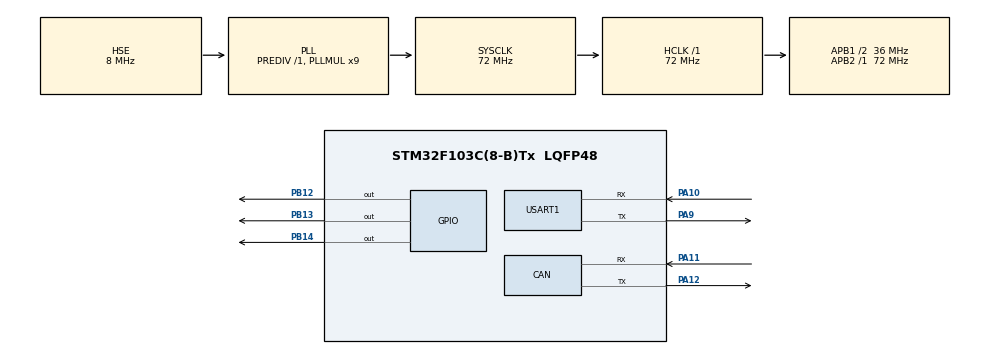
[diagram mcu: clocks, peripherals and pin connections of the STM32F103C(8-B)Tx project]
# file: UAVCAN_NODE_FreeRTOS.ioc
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CAN.CalculateTimeBit=1333
CAN.CalculateTimeQuantum=444.44444444444446
FREERTOS.Tasks01=Task01,0,128,StartTask01,Default,NULL,Dynamic,NULL,NULL;Task02,0,128,StartTask02,Default,NULL,Dynamic,NULL,NULL
Mcu.Family=STM32F1
Mcu.Name=STM32F103C(8-B)Tx
Mcu.Package=LQFP48
NVIC.PriorityGroup=NVIC_PRIORITYGROUP_4
NVIC.TIM4_IRQn=true\:0\:0\:false\:false\:true\:false\:false
NVIC.TimeBase=TIM4_IRQn
NVIC.TimeBaseIP=TIM4
NVIC.USART1_IRQn=true\:5\:0\:false\:false\:true\:true\:true
PA10.Mode=Asynchronous
PA10.Signal=USART1_RX
PA11.Mode=Master
PA11.Signal=CAN_RX
PA12.Mode=Master
PA12.Signal=CAN_TX
PA13.Mode=Trace_Asynchronous_SW
PA13.Signal=SYS_JTMS-SWDIO
PA14.Mode=Trace_Asynchronous_SW
PA14.Signal=SYS_JTCK-SWCLK
PA9.Mode=Asynchronous
PA9.Signal=USART1_TX
PB12.PinState=GPIO_PIN_SET
PB12.Signal=GPIO_Output
PB13.PinState=GPIO_PIN_SET
PB13.Signal=GPIO_Output
PB14.PinState=GPIO_PIN_SET
PB14.Signal=GPIO_Output
PB3.Mode=Trace_Asynchronous_SW
PB3.Signal=SYS_JTDO-TRACESWO
PD0-OSC_IN.Mode=HSE-External-Oscillator
PD0-OSC_IN.Signal=RCC_OSC_IN
PD1-OSC_OUT.Mode=HSE-External-Oscillator
PD1-OSC_OUT.Signal=RCC_OSC_OUT
ProjectManager.HeapSize=0x200
ProjectManager.StackSize=0x400
ProjectManager.TargetToolchain=Makefile
RCC.AHBFreq_Value=72000000
RCC.APB1CLKDivider=RCC_HCLK_DIV2
RCC.APB1Freq_Value=36000000
RCC.APB1TimFreq_Value=72000000
RCC.APB2Freq_Value=72000000
RCC.APB2TimFreq_Value=72000000
RCC.HCLKFreq_Value=72000000
RCC.PLLMUL=RCC_PLL_MUL9
RCC.PLLSourceVirtual=RCC_PLLSOURCE_HSE
RCC.SYSCLKFreq_VALUE=72000000
RCC.SYSCLKSource=RCC_SYSCLKSOURCE_PLLCLK
RCC.USBFreq_Value=72000000
USART1.VirtualMode=VM_ASYNC
VP_FREERTOS_VS_ENABLE.Mode=Enabled
VP_SYS_VS_tim4.Mode=TIM4
board=custom

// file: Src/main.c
/**
  ******************************************************************************
  * @file           : main.c
  * @brief          : Main program body
  ******************************************************************************
  * This notice applies to any and all portions of this file
  * that are not between comment pairs USER CODE BEGIN and
  * USER CODE END. Other portions of this file, whether
  * inserted by the user or by software development tools
  * are owned by their respective copyright owners.
  *
  * Copyright (c) 2018 STMicroelectronics International N.V.
  * All rights reserved.
  *
  * Redistribution and use in source and binary forms, with or without
  * modification, are permitted, provided that the following conditions are met:
  *
  * 1. Redistribution of source code must retain the above copyright notice,
  *    this list of conditions and the following disclaimer.
  * 2. Redistributions in binary form must reproduce the above copyright notice,
  *    this list of conditions and the following disclaimer in the documentation
  *    and/or other materials provided with the distribution.
  * 3. Neither the name of STMicroelectronics nor the names of other
  *    contributors to this software may be used to endorse or promote products
  *    derived from this software without specific written permission.
  * 4. This software, including modifications and/or derivative works of this
  *    software, must execute solely and exclusively on microcontroller or
  *    microprocessor devices manufactured by or for STMicroelectronics.
  * 5. Redistribution and use of this software other than as permitted under
  *    this license is void and will automatically terminate your rights under
  *    this license.
  *
  * THIS SOFTWARE IS PROVIDED BY STMICROELECTRONICS AND CONTRIBUTORS "AS IS"
  * AND ANY EXPRESS, IMPLIED OR STATUTORY WARRANTIES, INCLUDING, BUT NOT
  * LIMITED TO, THE IMPLIED WARRANTIES OF MERCHANTABILITY, FITNESS FOR A
  * PARTICULAR PURPOSE AND NON-INFRINGEMENT OF THIRD PARTY INTELLECTUAL PROPERTY
  * RIGHTS ARE DISCLAIMED TO THE FULLEST EXTENT PERMITTED BY LAW. IN NO EVENT
  * SHALL STMICROELECTRONICS OR CONTRIBUTORS BE LIABLE FOR ANY DIRECT, INDIRECT,
  * INCIDENTAL, SPECIAL, EXEMPLARY, OR CONSEQUENTIAL DAMAGES (INCLUDING, BUT NOT
  * LIMITED TO, PROCUREMENT OF SUBSTITUTE GOODS OR SERVICES; LOSS OF USE, DATA,
  * OR PROFITS; OR BUSINESS INTERRUPTION) HOWEVER CAUSED AND ON ANY THEORY OF
  * LIABILITY, WHETHER IN CONTRACT, STRICT LIABILITY, OR TORT (INCLUDING
  * NEGLIGENCE OR OTHERWISE) ARISING IN ANY WAY OUT OF THE USE OF THIS SOFTWARE,
  * EVEN IF ADVISED OF THE POSSIBILITY OF SUCH DAMAGE.
  *
  ******************************************************************************
  */
#include "main.h"
#include "stm32f1xx_hal.h"
#include "cmsis_os.h"
#include "can.h"
#include "usart.h"
#include "gpio.h"
#include "uavcan.h"

/* USER CODE BEGIN PV */
/* Private variables ---------------------------------------------------------*/

/* USER CODE END PV */

void SystemClock_Config(void);
void MX_FREERTOS_Init(void);

/* USER CODE BEGIN PFP */
/* Private function prototypes -----------------------------------------------*/

/* USER CODE END PFP */

int main(void)
{

  /* MCU Configuration----------------------------------------------------------*/

  /* Reset of all peripherals, Initializes the Flash interface and the Systick. */
  HAL_Init();

  /* Configure the system clock */
  SystemClock_Config();

  /* Initialize all configured peripherals */
  MX_GPIO_Init();
  MX_USART1_UART_Init();
  MX_CAN_Init();
  /* USER CODE BEGIN 2 */
  uavcanInit();
  /* USER CODE END 2 */

  /* Call init function for freertos objects (in freertos.c) */
  MX_FREERTOS_Init();

  /* Start scheduler */
  osKernelStart();

  /* We should never get here as control is now taken by the scheduler */

  /* Infinite loop */
  while (1)
  {

  }

}

void SystemClock_Config(void)
{

  RCC_OscInitTypeDef RCC_OscInitStruct;
  RCC_ClkInitTypeDef RCC_ClkInitStruct;

    /**Initializes the CPU, AHB and APB busses clocks
    */
  RCC_OscInitStruct.OscillatorType = RCC_OSCILLATORTYPE_HSE;
  RCC_OscInitStruct.HSEState = RCC_HSE_ON;
  RCC_OscInitStruct.HSEPredivValue = RCC_HSE_PREDIV_DIV1;
  RCC_OscInitStruct.HSIState = RCC_HSI_ON;
  RCC_OscInitStruct.PLL.PLLState = RCC_PLL_ON;
  RCC_OscInitStruct.PLL.PLLSource = RCC_PLLSOURCE_HSE;
  RCC_OscInitStruct.PLL.PLLMUL = RCC_PLL_MUL9;
  if (HAL_RCC_OscConfig(&RCC_OscInitStruct) != HAL_OK)
  {
    _Error_Handler(__FILE__, __LINE__);
  }

    /**Initializes the CPU, AHB and APB busses clocks
    */
  RCC_ClkInitStruct.ClockType = RCC_CLOCKTYPE_HCLK|RCC_CLOCKTYPE_SYSCLK
                              |RCC_CLOCKTYPE_PCLK1|RCC_CLOCKTYPE_PCLK2;
  RCC_ClkInitStruct.SYSCLKSource = RCC_SYSCLKSOURCE_PLLCLK;
  RCC_ClkInitStruct.AHBCLKDivider = RCC_SYSCLK_DIV1;
  RCC_ClkInitStruct.APB1CLKDivider = RCC_HCLK_DIV2;
  RCC_ClkInitStruct.APB2CLKDivider = RCC_HCLK_DIV1;

  if (HAL_RCC_ClockConfig(&RCC_ClkInitStruct, FLASH_LATENCY_2) != HAL_OK)
  {
    _Error_Handler(__FILE__, __LINE__);
  }

    /**Configure the Systick interrupt time
    */
  HAL_SYSTICK_Config(HAL_RCC_GetHCLKFreq()/1000);

    /**Configure the Systick
    */
  HAL_SYSTICK_CLKSourceConfig(SYSTICK_CLKSOURCE_HCLK);

  /* SysTick_IRQn interrupt configuration */
  HAL_NVIC_SetPriority(SysTick_IRQn, 15, 0);
}

void HAL_TIM_PeriodElapsedCallback(TIM_HandleTypeDef *htim)
{
  if (htim->Instance == TIM4) {
    HAL_IncTick();
  }
}

void _Error_Handler(char *file, int line)
{
  while(1)
  {
  }
}

/************************ (C) COPYRIGHT STMicroelectronics *****END OF FILE****/
